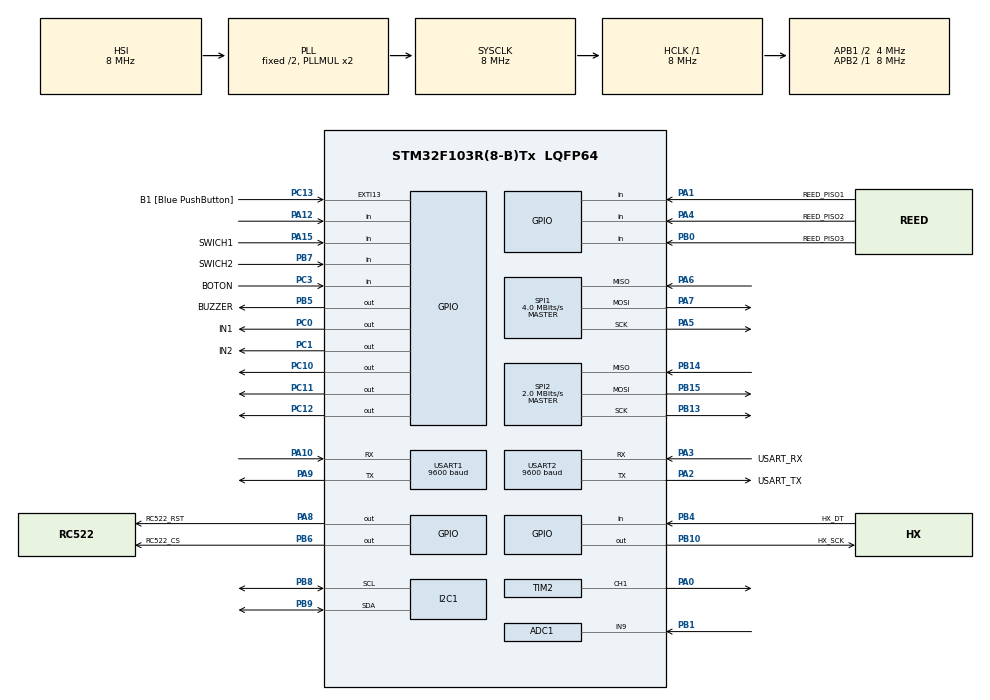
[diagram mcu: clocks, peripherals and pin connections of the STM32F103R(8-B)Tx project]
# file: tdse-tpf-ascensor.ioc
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ADC1.Channel-4\#ChannelRegularConversion=ADC_CHANNEL_9
ADC1.NbrOfConversionFlag=1
ADC1.Rank-4\#ChannelRegularConversion=1
ADC1.SamplingTime-4\#ChannelRegularConversion=ADC_SAMPLETIME_1CYCLE_5
ADC1.master=1
Mcu.Family=STM32F1
Mcu.Name=STM32F103R(8-B)Tx
Mcu.Package=LQFP64
NVIC.EXTI15_10_IRQn=true\:0\:0\:false\:false\:true\:true\:true\:true
NVIC.PriorityGroup=NVIC_PRIORITYGROUP_4
NVIC.USART2_IRQn=true\:0\:0\:false\:false\:true\:true\:true\:true
PA0-WKUP.Signal=S_TIM2_CH1_ETR
PA1.GPIO_Label=REED_PISO1
PA1.GPIO_PuPd=GPIO_PULLUP
PA1.Signal=GPIO_Input
PA10.Mode=Asynchronous
PA10.Signal=USART1_RX
PA12.Signal=GPIO_Input
PA13.GPIO_Label=TMS
PA13.Mode=Serial_Wire
PA13.Signal=SYS_JTMS-SWDIO
PA14.GPIO_Label=TCK
PA14.Mode=Serial_Wire
PA14.Signal=SYS_JTCK-SWCLK
PA15.GPIO_Label=SWICH1
PA15.GPIO_PuPd=GPIO_PULLUP
PA15.Signal=GPIO_Input
PA2.GPIO_Label=USART_TX
PA2.GPIO_Mode=GPIO_MODE_AF_PP
PA2.GPIO_PuPd=GPIO_NOPULL
PA2.GPIO_Speed=GPIO_SPEED_FREQ_LOW
PA2.Mode=Asynchronous
PA2.Signal=USART2_TX
PA3.GPIO_Label=USART_RX
PA3.GPIO_Mode=GPIO_MODE_AF_PP
PA3.GPIO_PuPd=GPIO_NOPULL
PA3.GPIO_Speed=GPIO_SPEED_FREQ_LOW
PA3.Mode=Asynchronous
PA3.Signal=USART2_RX
PA4.GPIO_Label=REED_PISO2
PA4.GPIO_PuPd=GPIO_PULLUP
PA4.Signal=GPIO_Input
PA5.Mode=Full_Duplex_Master
PA5.Signal=SPI1_SCK
PA6.Mode=Full_Duplex_Master
PA6.Signal=SPI1_MISO
PA7.Mode=Full_Duplex_Master
PA7.Signal=SPI1_MOSI
PA8.GPIO_Label=RC522_RST
PA8.Signal=GPIO_Output
PA9.Mode=Asynchronous
PA9.Signal=USART1_TX
PB0.GPIO_Label=REED_PISO3
PB0.GPIO_PuPd=GPIO_PULLUP
PB0.Signal=GPIO_Input
PB1.Signal=ADCx_IN9
PB10.GPIO_Label=HX_SCK
PB10.Signal=GPIO_Output
PB13.Mode=Full_Duplex_Master
PB13.Signal=SPI2_SCK
PB14.Mode=Full_Duplex_Master
PB14.Signal=SPI2_MISO
PB15.Mode=Full_Duplex_Master
PB15.Signal=SPI2_MOSI
PB3.GPIO_Label=SWO
PB3.Signal=SYS_JTDO-TRACESWO
PB4.GPIO_Label=HX_DT
PB4.Signal=GPIO_Input
PB5.GPIO_Label=BUZZER
PB5.Signal=GPIO_Output
PB6.GPIO_Label=RC522_CS
PB6.PinState=GPIO_PIN_SET
PB6.Signal=GPIO_Output
PB7.GPIO_Label=SWICH2
PB7.GPIO_PuPd=GPIO_PULLUP
PB7.Signal=GPIO_Input
PB8.Mode=I2C
PB8.Signal=I2C1_SCL
PB9.Mode=I2C
PB9.Signal=I2C1_SDA
PC0.GPIO_Label=IN1
PC0.Signal=GPIO_Output
PC1.GPIO_Label=IN2
PC1.Signal=GPIO_Output
PC10.Signal=GPIO_Output
PC11.Signal=GPIO_Output
PC12.Signal=GPIO_Output
PC13-TAMPER-RTC.GPIO_Label=B1 [Blue PushButton]
PC13-TAMPER-RTC.GPIO_PuPd=GPIO_NOPULL
PC13-TAMPER-RTC.Signal=GPXTI13
PC14-OSC32_IN.Mode=LSE-External-Oscillator
PC14-OSC32_IN.Signal=RCC_OSC32_IN
PC15-OSC32_OUT.Mode=LSE-External-Oscillator
PC15-OSC32_OUT.Signal=RCC_OSC32_OUT
PC3.GPIO_Label=BOTON
PC3.GPIO_PuPd=GPIO_PULLUP
PC3.Signal=GPIO_Input
PD0-OSC_IN.Mode=HSE-External-Clock-Source
PD0-OSC_IN.Signal=RCC_OSC_IN
PD1-OSC_OUT.Mode=HSE-External-Clock-Source
PD1-OSC_OUT.Signal=RCC_OSC_OUT
ProjectManager.HeapSize=0x200
ProjectManager.StackSize=0x400
ProjectManager.TargetToolchain=STM32CubeIDE
RCC.AHBFreq_Value=8000000
RCC.APB1CLKDivider=RCC_HCLK_DIV2
RCC.APB1Freq_Value=4000000
RCC.APB1TimFreq_Value=8000000
RCC.APB2Freq_Value=8000000
RCC.APB2TimFreq_Value=8000000
RCC.HCLKFreq_Value=8000000
RCC.RTCClockSelection=RCC_RTCCLKSOURCE_LSE
RCC.SYSCLKFreq_VALUE=8000000
RCC.SYSCLKSource=RCC_SYSCLKSOURCE_PLLCLK
RCC.USBFreq_Value=8000000
SH.ADCx_IN9.0=ADC1_IN9,IN9
SH.S_TIM2_CH1_ETR.0=TIM2_CH1,PWM Generation1 CH1
SPI1.CalculateBaudRate=4.0 MBits/s
SPI1.Direction=SPI_DIRECTION_2LINES
SPI1.Mode=SPI_MODE_MASTER
SPI1.VirtualType=VM_MASTER
SPI2.CalculateBaudRate=2.0 MBits/s
SPI2.Direction=SPI_DIRECTION_2LINES
SPI2.Mode=SPI_MODE_MASTER
SPI2.VirtualType=VM_MASTER
TIM2.Channel-PWM\ Generation1\ CH1=TIM_CHANNEL_1
TIM2.Period=999
TIM2.Prescaler=71
USART1.BaudRate=9600
USART1.VirtualMode=VM_ASYNC
USART2.BaudRate=9600
USART2.VirtualMode=VM_ASYNC
board=NUCLEO-F103RB

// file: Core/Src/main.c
/* USER CODE BEGIN Header */
/**
  ******************************************************************************
  * @file           : main.c
  * @brief          : Main program body
  ******************************************************************************
  * @attention
  *
  * Copyright (c) 2024 STMicroelectronics.
  * All rights reserved.
  *
  * This software is licensed under terms that can be found in the LICENSE file
  * in the root directory of this software component.
  * If no LICENSE file comes with this software, it is provided AS-IS.
  *
  ******************************************************************************
  */
/* USER CODE END Header */
#include "main.h"

/* USER CODE BEGIN Includes */
#include "app.h"
/* USER CODE END Includes */

ADC_HandleTypeDef hadc1;

I2C_HandleTypeDef hi2c1;

SPI_HandleTypeDef hspi1;
SPI_HandleTypeDef hspi2;

TIM_HandleTypeDef htim2;

UART_HandleTypeDef huart1;
UART_HandleTypeDef huart2;

void SystemClock_Config(void);
static void MX_GPIO_Init(void);
static void MX_USART2_UART_Init(void);
static void MX_I2C1_Init(void);
static void MX_TIM2_Init(void);
static void MX_SPI2_Init(void);
static void MX_USART1_UART_Init(void);
static void MX_SPI1_Init(void);
static void MX_ADC1_Init(void);
/* USER CODE BEGIN PFP */
extern void initialise_monitor_handles(void);
/* USER CODE END PFP */

int main(void)
{

  /* USER CODE BEGIN 1 */

	initialise_monitor_handles();
  /* USER CODE END 1 */

  /* MCU Configuration--------------------------------------------------------*/

  /* Reset of all peripherals, Initializes the Flash interface and the Systick. */
  HAL_Init();

  /* Configure the system clock */
  SystemClock_Config();

  /* Initialize all configured peripherals */
  MX_GPIO_Init();
  MX_USART2_UART_Init();
  MX_I2C1_Init();
  MX_TIM2_Init();
  MX_SPI2_Init();
  MX_USART1_UART_Init();
  MX_SPI1_Init();
  MX_ADC1_Init();
  /* USER CODE BEGIN 2 */
    app_init();

    // Le decimos explícitamente al puerto USART2 que espere 1 byte

  /* USER CODE END 2 */

  /* Infinite loop */
  /* USER CODE BEGIN WHILE */
    /* Infinite loop */
      /* USER CODE BEGIN WHILE */
      while (1)
      {
          app_update(); // Tu ejecutor cíclico

          // --- MODO BAJO CONSUMO ---
          // El microcontrolador se duerme acá. El consumo de corriente cae drásticamente.
          // Se va a despertar automáticamente en el próximo milisegundo por el Systick,
          // o si llega un dato por el puerto serial del Bluetooth.
          //__WFI();

    /* USER CODE END WHILE */

  }
}

void SystemClock_Config(void)
{
  RCC_OscInitTypeDef RCC_OscInitStruct = {0};
  RCC_ClkInitTypeDef RCC_ClkInitStruct = {0};
  RCC_PeriphCLKInitTypeDef PeriphClkInit = {0};

  /** Initializes the RCC Oscillators according to the specified parameters
  * in the RCC_OscInitTypeDef structure.
  */
  RCC_OscInitStruct.OscillatorType = RCC_OSCILLATORTYPE_HSI;
  RCC_OscInitStruct.HSIState = RCC_HSI_ON;
  RCC_OscInitStruct.HSICalibrationValue = RCC_HSICALIBRATION_DEFAULT;
  RCC_OscInitStruct.PLL.PLLState = RCC_PLL_ON;
  RCC_OscInitStruct.PLL.PLLSource = RCC_PLLSOURCE_HSI_DIV2;
  RCC_OscInitStruct.PLL.PLLMUL = RCC_PLL_MUL2;
  if (HAL_RCC_OscConfig(&RCC_OscInitStruct) != HAL_OK)
  {
    Error_Handler();
  }

  /** Initializes the CPU, AHB and APB buses clocks
  */
  RCC_ClkInitStruct.ClockType = RCC_CLOCKTYPE_HCLK|RCC_CLOCKTYPE_SYSCLK
                              |RCC_CLOCKTYPE_PCLK1|RCC_CLOCKTYPE_PCLK2;
  RCC_ClkInitStruct.SYSCLKSource = RCC_SYSCLKSOURCE_PLLCLK;
  RCC_ClkInitStruct.AHBCLKDivider = RCC_SYSCLK_DIV1;
  RCC_ClkInitStruct.APB1CLKDivider = RCC_HCLK_DIV2;
  RCC_ClkInitStruct.APB2CLKDivider = RCC_HCLK_DIV1;

  if (HAL_RCC_ClockConfig(&RCC_ClkInitStruct, FLASH_LATENCY_0) != HAL_OK)
  {
    Error_Handler();
  }
  PeriphClkInit.PeriphClockSelection = RCC_PERIPHCLK_ADC;
  PeriphClkInit.AdcClockSelection = RCC_ADCPCLK2_DIV2;
  if (HAL_RCCEx_PeriphCLKConfig(&PeriphClkInit) != HAL_OK)
  {
    Error_Handler();
  }
}

static void MX_ADC1_Init(void)
{

  ADC_ChannelConfTypeDef sConfig = {0};

  /** Common config
  */
  hadc1.Instance = ADC1;
  hadc1.Init.ScanConvMode = ADC_SCAN_DISABLE;
  hadc1.Init.ContinuousConvMode = DISABLE;
  hadc1.Init.DiscontinuousConvMode = DISABLE;
  hadc1.Init.ExternalTrigConv = ADC_SOFTWARE_START;
  hadc1.Init.DataAlign = ADC_DATAALIGN_RIGHT;
  hadc1.Init.NbrOfConversion = 1;
  if (HAL_ADC_Init(&hadc1) != HAL_OK)
  {
    Error_Handler();
  }

  /** Configure Regular Channel
  */
  sConfig.Channel = ADC_CHANNEL_9;
  sConfig.Rank = ADC_REGULAR_RANK_1;
  sConfig.SamplingTime = ADC_SAMPLETIME_1CYCLE_5;
  if (HAL_ADC_ConfigChannel(&hadc1, &sConfig) != HAL_OK)
  {
    Error_Handler();
  }

}

static void MX_I2C1_Init(void)
{

  hi2c1.Instance = I2C1;
  hi2c1.Init.ClockSpeed = 100000;
  hi2c1.Init.DutyCycle = I2C_DUTYCYCLE_2;
  hi2c1.Init.OwnAddress1 = 0;
  hi2c1.Init.AddressingMode = I2C_ADDRESSINGMODE_7BIT;
  hi2c1.Init.DualAddressMode = I2C_DUALADDRESS_DISABLE;
  hi2c1.Init.OwnAddress2 = 0;
  hi2c1.Init.GeneralCallMode = I2C_GENERALCALL_DISABLE;
  hi2c1.Init.NoStretchMode = I2C_NOSTRETCH_DISABLE;
  if (HAL_I2C_Init(&hi2c1) != HAL_OK)
  {
    Error_Handler();
  }

}

static void MX_SPI1_Init(void)
{

  /* SPI1 parameter configuration*/
  hspi1.Instance = SPI1;
  hspi1.Init.Mode = SPI_MODE_MASTER;
  hspi1.Init.Direction = SPI_DIRECTION_2LINES;
  hspi1.Init.DataSize = SPI_DATASIZE_8BIT;
  hspi1.Init.CLKPolarity = SPI_POLARITY_LOW;
  hspi1.Init.CLKPhase = SPI_PHASE_1EDGE;
  hspi1.Init.NSS = SPI_NSS_SOFT;
  hspi1.Init.BaudRatePrescaler = SPI_BAUDRATEPRESCALER_2;
  hspi1.Init.FirstBit = SPI_FIRSTBIT_MSB;
  hspi1.Init.TIMode = SPI_TIMODE_DISABLE;
  hspi1.Init.CRCCalculation = SPI_CRCCALCULATION_DISABLE;
  hspi1.Init.CRCPolynomial = 10;
  if (HAL_SPI_Init(&hspi1) != HAL_OK)
  {
    Error_Handler();
  }

}

static void MX_SPI2_Init(void)
{

  /* SPI2 parameter configuration*/
  hspi2.Instance = SPI2;
  hspi2.Init.Mode = SPI_MODE_MASTER;
  hspi2.Init.Direction = SPI_DIRECTION_2LINES;
  hspi2.Init.DataSize = SPI_DATASIZE_8BIT;
  hspi2.Init.CLKPolarity = SPI_POLARITY_LOW;
  hspi2.Init.CLKPhase = SPI_PHASE_1EDGE;
  hspi2.Init.NSS = SPI_NSS_SOFT;
  hspi2.Init.BaudRatePrescaler = SPI_BAUDRATEPRESCALER_2;
  hspi2.Init.FirstBit = SPI_FIRSTBIT_MSB;
  hspi2.Init.TIMode = SPI_TIMODE_DISABLE;
  hspi2.Init.CRCCalculation = SPI_CRCCALCULATION_DISABLE;
  hspi2.Init.CRCPolynomial = 10;
  if (HAL_SPI_Init(&hspi2) != HAL_OK)
  {
    Error_Handler();
  }

}

static void MX_TIM2_Init(void)
{

  TIM_MasterConfigTypeDef sMasterConfig = {0};
  TIM_OC_InitTypeDef sConfigOC = {0};

  htim2.Instance = TIM2;
  htim2.Init.Prescaler = 71;
  htim2.Init.CounterMode = TIM_COUNTERMODE_UP;
  htim2.Init.Period = 999;
  htim2.Init.ClockDivision = TIM_CLOCKDIVISION_DIV1;
  htim2.Init.AutoReloadPreload = TIM_AUTORELOAD_PRELOAD_DISABLE;
  if (HAL_TIM_PWM_Init(&htim2) != HAL_OK)
  {
    Error_Handler();
  }
  sMasterConfig.MasterOutputTrigger = TIM_TRGO_RESET;
  sMasterConfig.MasterSlaveMode = TIM_MASTERSLAVEMODE_DISABLE;
  if (HAL_TIMEx_MasterConfigSynchronization(&htim2, &sMasterConfig) != HAL_OK)
  {
    Error_Handler();
  }
  sConfigOC.OCMode = TIM_OCMODE_PWM1;
  sConfigOC.Pulse = 0;
  sConfigOC.OCPolarity = TIM_OCPOLARITY_HIGH;
  sConfigOC.OCFastMode = TIM_OCFAST_DISABLE;
  if (HAL_TIM_PWM_ConfigChannel(&htim2, &sConfigOC, TIM_CHANNEL_1) != HAL_OK)
  {
    Error_Handler();
  }
  HAL_TIM_MspPostInit(&htim2);

}

static void MX_USART1_UART_Init(void)
{

  huart1.Instance = USART1;
  huart1.Init.BaudRate = 9600;
  huart1.Init.WordLength = UART_WORDLENGTH_8B;
  huart1.Init.StopBits = UART_STOPBITS_1;
  huart1.Init.Parity = UART_PARITY_NONE;
  huart1.Init.Mode = UART_MODE_TX_RX;
  huart1.Init.HwFlowCtl = UART_HWCONTROL_NONE;
  huart1.Init.OverSampling = UART_OVERSAMPLING_16;
  if (HAL_UART_Init(&huart1) != HAL_OK)
  {
    Error_Handler();
  }

}

static void MX_USART2_UART_Init(void)
{

  huart2.Instance = USART2;
  huart2.Init.BaudRate = 9600;
  huart2.Init.WordLength = UART_WORDLENGTH_8B;
  huart2.Init.StopBits = UART_STOPBITS_1;
  huart2.Init.Parity = UART_PARITY_NONE;
  huart2.Init.Mode = UART_MODE_TX_RX;
  huart2.Init.HwFlowCtl = UART_HWCONTROL_NONE;
  huart2.Init.OverSampling = UART_OVERSAMPLING_16;
  if (HAL_UART_Init(&huart2) != HAL_OK)
  {
    Error_Handler();
  }

}

static void MX_GPIO_Init(void)
{
  GPIO_InitTypeDef GPIO_InitStruct = {0};

  /* GPIO Ports Clock Enable */
  __HAL_RCC_GPIOC_CLK_ENABLE();
  __HAL_RCC_GPIOD_CLK_ENABLE();
  __HAL_RCC_GPIOA_CLK_ENABLE();
  __HAL_RCC_GPIOB_CLK_ENABLE();

  /*Configure GPIO pin Output Level */
  HAL_GPIO_WritePin(GPIOC, IN1_Pin|IN2_Pin|GPIO_PIN_10|GPIO_PIN_11
                          |GPIO_PIN_12, GPIO_PIN_RESET);

  /*Configure GPIO pin Output Level */
  HAL_GPIO_WritePin(GPIOB, HX_SCK_Pin|BUZZER_Pin, GPIO_PIN_RESET);

  /*Configure GPIO pin Output Level */
  HAL_GPIO_WritePin(RC522_RST_GPIO_Port, RC522_RST_Pin, GPIO_PIN_RESET);

  /*Configure GPIO pin Output Level */
  HAL_GPIO_WritePin(RC522_CS_GPIO_Port, RC522_CS_Pin, GPIO_PIN_SET);

  /*Configure GPIO pin : B1_Pin */
  GPIO_InitStruct.Pin = B1_Pin;
  GPIO_InitStruct.Mode = GPIO_MODE_IT_RISING;
  GPIO_InitStruct.Pull = GPIO_NOPULL;
  HAL_GPIO_Init(B1_GPIO_Port, &GPIO_InitStruct);

  /*Configure GPIO pins : IN1_Pin IN2_Pin PC10 PC11
                           PC12 */
  GPIO_InitStruct.Pin = IN1_Pin|IN2_Pin|GPIO_PIN_10|GPIO_PIN_11
                          |GPIO_PIN_12;
  GPIO_InitStruct.Mode = GPIO_MODE_OUTPUT_PP;
  GPIO_InitStruct.Pull = GPIO_NOPULL;
  GPIO_InitStruct.Speed = GPIO_SPEED_FREQ_LOW;
  HAL_GPIO_Init(GPIOC, &GPIO_InitStruct);

  /*Configure GPIO pin : BOTON_Pin */
  GPIO_InitStruct.Pin = BOTON_Pin;
  GPIO_InitStruct.Mode = GPIO_MODE_INPUT;
  GPIO_InitStruct.Pull = GPIO_PULLUP;
  HAL_GPIO_Init(BOTON_GPIO_Port, &GPIO_InitStruct);

  /*Configure GPIO pins : REED_PISO1_Pin REED_PISO2_Pin SWICH1_Pin */
  GPIO_InitStruct.Pin = REED_PISO1_Pin|REED_PISO2_Pin|SWICH1_Pin;
  GPIO_InitStruct.Mode = GPIO_MODE_INPUT;
  GPIO_InitStruct.Pull = GPIO_PULLUP;
  HAL_GPIO_Init(GPIOA, &GPIO_InitStruct);

  /*Configure GPIO pins : REED_PISO3_Pin SWICH2_Pin */
  GPIO_InitStruct.Pin = REED_PISO3_Pin|SWICH2_Pin;
  GPIO_InitStruct.Mode = GPIO_MODE_INPUT;
  GPIO_InitStruct.Pull = GPIO_PULLUP;
  HAL_GPIO_Init(GPIOB, &GPIO_InitStruct);

  /*Configure GPIO pins : HX_SCK_Pin BUZZER_Pin RC522_CS_Pin */
  GPIO_InitStruct.Pin = HX_SCK_Pin|BUZZER_Pin|RC522_CS_Pin;
  GPIO_InitStruct.Mode = GPIO_MODE_OUTPUT_PP;
  GPIO_InitStruct.Pull = GPIO_NOPULL;
  GPIO_InitStruct.Speed = GPIO_SPEED_FREQ_LOW;
  HAL_GPIO_Init(GPIOB, &GPIO_InitStruct);

  /*Configure GPIO pin : RC522_RST_Pin */
  GPIO_InitStruct.Pin = RC522_RST_Pin;
  GPIO_InitStruct.Mode = GPIO_MODE_OUTPUT_PP;
  GPIO_InitStruct.Pull = GPIO_NOPULL;
  GPIO_InitStruct.Speed = GPIO_SPEED_FREQ_LOW;
  HAL_GPIO_Init(RC522_RST_GPIO_Port, &GPIO_InitStruct);

  /*Configure GPIO pin : PA12 */
  GPIO_InitStruct.Pin = GPIO_PIN_12;
  GPIO_InitStruct.Mode = GPIO_MODE_INPUT;
  GPIO_InitStruct.Pull = GPIO_NOPULL;
  HAL_GPIO_Init(GPIOA, &GPIO_InitStruct);

  /*Configure GPIO pin : HX_DT_Pin */
  GPIO_InitStruct.Pin = HX_DT_Pin;
  GPIO_InitStruct.Mode = GPIO_MODE_INPUT;
  GPIO_InitStruct.Pull = GPIO_NOPULL;
  HAL_GPIO_Init(HX_DT_GPIO_Port, &GPIO_InitStruct);

  /* EXTI interrupt init*/
  HAL_NVIC_SetPriority(EXTI15_10_IRQn, 0, 0);
  HAL_NVIC_EnableIRQ(EXTI15_10_IRQn);

}

/* USER CODE BEGIN 4 */

extern shared_data_type shared_data; // Traemos la estructura global de tu app
uint8_t dato_bt;

int _kill(int pid, int sig) {
    return -1;
}

int _getpid(void) {
    return 1;
}
/* USER CODE END 4 */

void Error_Handler(void)
{
  __disable_irq();
  while (1)
  {
  }
}
